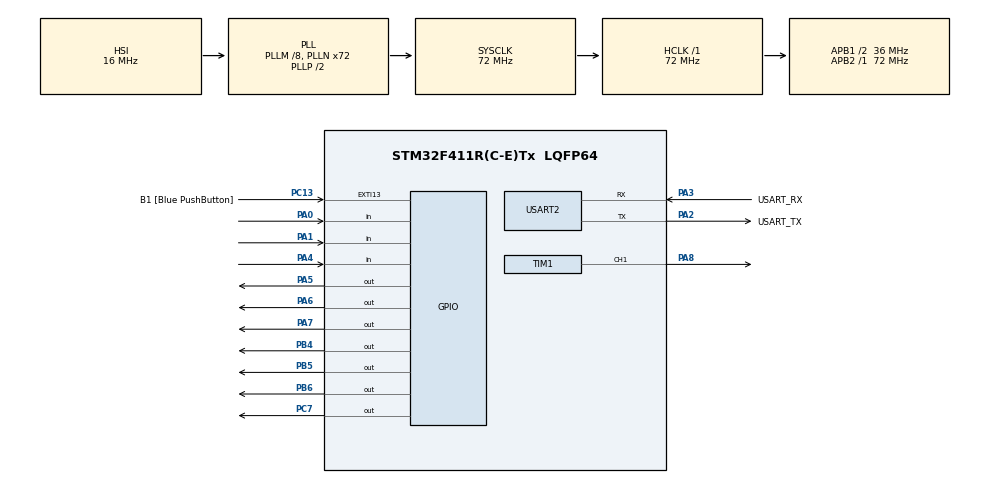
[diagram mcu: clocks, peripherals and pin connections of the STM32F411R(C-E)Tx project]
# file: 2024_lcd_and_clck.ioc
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Dma.Request0=TIM1_CH1
Dma.TIM1_CH1.0.Direction=DMA_PERIPH_TO_MEMORY
Dma.TIM1_CH1.0.FIFOMode=DMA_FIFOMODE_DISABLE
Dma.TIM1_CH1.0.Instance=DMA2_Stream1
Dma.TIM1_CH1.0.MemDataAlignment=DMA_MDATAALIGN_WORD
Dma.TIM1_CH1.0.MemInc=DMA_MINC_ENABLE
Dma.TIM1_CH1.0.Mode=DMA_NORMAL
Dma.TIM1_CH1.0.PeriphDataAlignment=DMA_PDATAALIGN_WORD
Dma.TIM1_CH1.0.PeriphInc=DMA_PINC_DISABLE
Dma.TIM1_CH1.0.Priority=DMA_PRIORITY_LOW
Mcu.Family=STM32F4
Mcu.Name=STM32F411R(C-E)Tx
Mcu.Package=LQFP64
NVIC.DMA2_Stream1_IRQn=true\:0\:0\:false\:false\:true\:false\:true\:true
NVIC.PriorityGroup=NVIC_PRIORITYGROUP_0
PA0-WKUP.Signal=GPIO_Input
PA1.Signal=GPIO_Input
PA13.GPIO_Label=TMS
PA13.Mode=Serial_Wire
PA13.Signal=SYS_JTMS-SWDIO
PA14.GPIO_Label=TCK
PA14.Mode=Serial_Wire
PA14.Signal=SYS_JTCK-SWCLK
PA2.GPIO_Label=USART_TX
PA2.Mode=Asynchronous
PA2.Signal=USART2_TX
PA3.GPIO_Label=USART_RX
PA3.Mode=Asynchronous
PA3.Signal=USART2_RX
PA4.Signal=GPIO_Input
PA5.Signal=GPIO_Output
PA6.Signal=GPIO_Output
PA7.Signal=GPIO_Output
PA8.Signal=S_TIM1_CH1
PB3.Signal=SYS_JTDO-SWO
PB4.Signal=GPIO_Output
PB5.Signal=GPIO_Output
PB6.Signal=GPIO_Output
PC13-ANTI_TAMP.GPIO_Label=B1 [Blue PushButton]
PC13-ANTI_TAMP.GPIO_ModeDefaultEXTI=GPIO_MODE_IT_FALLING
PC13-ANTI_TAMP.Signal=GPXTI13
PC14-OSC32_IN.Mode=LSE-External-Oscillator
PC14-OSC32_IN.Signal=RCC_OSC32_IN
PC15-OSC32_OUT.Mode=LSE-External-Oscillator
PC15-OSC32_OUT.Signal=RCC_OSC32_OUT
PC7.Signal=GPIO_Output
PH0\ -\ OSC_IN.Mode=HSE-External-Oscillator
PH0\ -\ OSC_IN.Signal=RCC_OSC_IN
PH1\ -\ OSC_OUT.Mode=HSE-External-Oscillator
PH1\ -\ OSC_OUT.Signal=RCC_OSC_OUT
ProjectManager.HeapSize=0x200
ProjectManager.StackSize=0x400
ProjectManager.TargetToolchain=STM32CubeIDE
RCC.48MHZClocksFreq_Value=36000000
RCC.AHBFreq_Value=72000000
RCC.APB1CLKDivider=RCC_HCLK_DIV2
RCC.APB1Freq_Value=36000000
RCC.APB1TimFreq_Value=72000000
RCC.APB2Freq_Value=72000000
RCC.APB2TimFreq_Value=72000000
RCC.CortexFreq_Value=72000000
RCC.FLatency-AdvancedSettings=FLASH_LATENCY_2
RCC.HCLKFreq_Value=72000000
RCC.HSE_VALUE=8000000
RCC.HSI_VALUE=16000000
RCC.PLLM=8
RCC.PLLN=72
RCC.SYSCLKFreq_VALUE=72000000
RCC.SYSCLKSource=RCC_SYSCLKSOURCE_PLLCLK
RCC.VCOOutputFreq_Value=144000000
SH.S_TIM1_CH1.0=TIM1_CH1,PWM Generation1 CH1
TIM1.AutoReloadPreload=TIM_AUTORELOAD_PRELOAD_ENABLE
TIM1.Channel-PWM\ Generation1\ CH1=TIM_CHANNEL_1
TIM1.Period=100
TIM1.Pulse-PWM\ Generation1\ CH1=25
USART2.VirtualMode=VM_ASYNC
VP_TIM1_VS_ClockSourceINT.Mode=Internal
board=NUCLEO-F411RE

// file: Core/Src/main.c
/* USER CODE BEGIN Header */
/**
 ******************************************************************************
 * @file           : main.c
 * @brief          : Main program body
 ******************************************************************************
 * @attention
 *
 * Copyright (c) 2024 STMicroelectronics.
 * All rights reserved.
 *
 * This software is licensed under terms that can be found in the LICENSE file
 * in the root directory of this software component.
 * If no LICENSE file comes with this software, it is provided AS-IS.
 *
 ******************************************************************************
 */
/* USER CODE END Header */
#include "main.h"

/* USER CODE BEGIN Includes */
#include "lcd.h"
/* USER CODE END Includes */

TIM_HandleTypeDef htim1;
DMA_HandleTypeDef hdma_tim1_ch1;

UART_HandleTypeDef huart2;

/* USER CODE BEGIN PV */
char buffer[40];
uint32_t time;
int waiting_time_for_push = 3000000, pa0Push, push_delay = 500, seconds;
int b, a, pwmPulse, light_sensor;
/* USER CODE END PV */

void SystemClock_Config(void);
static void MX_GPIO_Init(void);
static void MX_DMA_Init(void);
static void MX_USART2_UART_Init(void);
static void MX_TIM1_Init(void);

int main(void)
{

  /* MCU Configuration--------------------------------------------------------*/

  /* Reset of all peripherals, Initializes the Flash interface and the Systick. */
  HAL_Init();

  /* Configure the system clock */
  SystemClock_Config();

  /* Initialize all configured peripherals */
  MX_GPIO_Init();
  MX_DMA_Init();
  MX_USART2_UART_Init();
  MX_TIM1_Init();
  /* USER CODE BEGIN 2 */

  HAL_TIM_PWM_Start(&htim1, TIM_CHANNEL_1);

	Lcd_PortType ports[] = { GPIOC, GPIOB, GPIOA, GPIOA };
	// Lcd_PinType pins[] = {D4_Pin, D5_Pin, D6_Pin, D7_Pin};
	Lcd_PinType pins[] = {GPIO_PIN_7, GPIO_PIN_6, GPIO_PIN_7, GPIO_PIN_6};
	Lcd_HandleTypeDef lcd;
	// Lcd_create(ports, pins, RS_GPIO_Port, RS_Pin, EN_GPIO_Port, EN_Pin, LCD_4_BIT_MODE);
	lcd = Lcd_create(ports, pins, GPIOB, GPIO_PIN_5, GPIOB, GPIO_PIN_4, LCD_4_BIT_MODE);
	Lcd_cursor(&lcd, 0,1);
	Lcd_string(&lcd, "SECONDS OF START");
  /* USER CODE END 2 */

  /* Infinite loop */
	while (1)
	{

		__HAL_TIM_SET_COMPARE(&htim1, TIM_CHANNEL_1,pwmPulse);
		//------------------------

				time = HAL_GetTick();
				   Lcd_cursor(&lcd, 0,18);
				       Lcd_int(&lcd, time/1000);

				//"a" is main menu number
				if(a < 0){a = 0;}
				if(a > 5){a = 5;}
				sprintf(buffer, " Manual pwm  %d \r\n", b);
				HAL_UART_Transmit(&huart2, buffer, sizeof(buffer), HAL_MAX_DELAY);
				sprintf(buffer, "	Set number  %d \r\n",a);
				HAL_UART_Transmit(&huart2, buffer, sizeof(buffer), HAL_MAX_DELAY);

				if((b == 0))
				{pa0Push =0;
				pwmPulse = light_sensor;

				sprintf(buffer, "AUTO PWM  \r\n");
				HAL_UART_Transmit(&huart2, buffer, sizeof(buffer), HAL_MAX_DELAY);
				Lcd_cursor(&lcd, 1,1);
				Lcd_string(&lcd, "AUTO PWM                  ");

				while (HAL_GPIO_ReadPin (GPIOA, GPIO_PIN_4))
				{
					pa0Push++;

					if ( (pa0Push > waiting_time_for_push) )

					{	 b = 1;
					break;

					}
				}
				}

				if(b == 1)
				{
					pa0Push = 0;
					Lcd_cursor(&lcd, 1,1);
					Lcd_string(&lcd, "MANUAL PWM SET");

					if (HAL_GPIO_ReadPin (GPIOA, GPIO_PIN_0))
							{  a++;	//menu plus
							HAL_Delay (200);
							}

							if (HAL_GPIO_ReadPin (GPIOA, GPIO_PIN_1))
							{  a--;	//menu minus
							HAL_Delay (200);
							}

							if(a == 0)
																{
																	sprintf(buffer, "PWM OFF		\r\n");
																	HAL_UART_Transmit(&huart2, buffer, sizeof(buffer), HAL_MAX_DELAY);
																	Lcd_cursor(&lcd, 1,16);
																	Lcd_string(&lcd, "PWM OFF");
																	pwmPulse = 0;
																}

							if(a == 1)
											{
												sprintf(buffer, "PWM 20%%		\r\n");
												HAL_UART_Transmit(&huart2, buffer, sizeof(buffer), HAL_MAX_DELAY);
												Lcd_cursor(&lcd, 1,16);
												Lcd_string(&lcd, "PWM 20%            ");
												pwmPulse = 20;
											}
							if(a == 2)
																{
																	sprintf(buffer, "PWM 40%		\r\n");
																	HAL_UART_Transmit(&huart2, buffer, sizeof(buffer), HAL_MAX_DELAY);
																	Lcd_cursor(&lcd, 1,16);
																	Lcd_string(&lcd, "PWM 40%       ");
																	pwmPulse = 40;
																}
							if(a == 3)
																{
																	sprintf(buffer, "PWM 60% \r\n");
																	HAL_UART_Transmit(&huart2, buffer, sizeof(buffer), HAL_MAX_DELAY);
																	Lcd_cursor(&lcd, 1,16);
																	Lcd_string(&lcd, "PWM 60%  ");
																	pwmPulse =60;
																}
							if(a == 4)
																			{
																				sprintf(buffer, "PWM 80% \r\n");
																				HAL_UART_Transmit(&huart2, buffer, sizeof(buffer), HAL_MAX_DELAY);
																				Lcd_cursor(&lcd, 1,16);
																				Lcd_string(&lcd, "PWM 80%  ");
																				pwmPulse = 80;
																			}
							if(a == 5)
																			{
																				sprintf(buffer, "PWM 100% \r\n");
																				HAL_UART_Transmit(&huart2, buffer, sizeof(buffer), HAL_MAX_DELAY);
																				Lcd_cursor(&lcd, 1,16);
																				Lcd_string(&lcd, "PWM 100% ");
																				pwmPulse =100;
																			}

					while (HAL_GPIO_ReadPin (GPIOA, GPIO_PIN_4))
					{
						pa0Push++;

						if ( (pa0Push > waiting_time_for_push) )

						{	 b = 0;
						break;
						}
					}
				}

		//----------------
	}
}

void SystemClock_Config(void)
{
  RCC_OscInitTypeDef RCC_OscInitStruct = {0};
  RCC_ClkInitTypeDef RCC_ClkInitStruct = {0};

  /** Configure the main internal regulator output voltage
  */
  __HAL_RCC_PWR_CLK_ENABLE();
  __HAL_PWR_VOLTAGESCALING_CONFIG(PWR_REGULATOR_VOLTAGE_SCALE1);

  /** Initializes the RCC Oscillators according to the specified parameters
  * in the RCC_OscInitTypeDef structure.
  */
  RCC_OscInitStruct.OscillatorType = RCC_OSCILLATORTYPE_HSI;
  RCC_OscInitStruct.HSIState = RCC_HSI_ON;
  RCC_OscInitStruct.HSICalibrationValue = RCC_HSICALIBRATION_DEFAULT;
  RCC_OscInitStruct.PLL.PLLState = RCC_PLL_ON;
  RCC_OscInitStruct.PLL.PLLSource = RCC_PLLSOURCE_HSI;
  RCC_OscInitStruct.PLL.PLLM = 8;
  RCC_OscInitStruct.PLL.PLLN = 72;
  RCC_OscInitStruct.PLL.PLLP = RCC_PLLP_DIV2;
  RCC_OscInitStruct.PLL.PLLQ = 4;
  if (HAL_RCC_OscConfig(&RCC_OscInitStruct) != HAL_OK)
  {
    Error_Handler();
  }

  /** Initializes the CPU, AHB and APB buses clocks
  */
  RCC_ClkInitStruct.ClockType = RCC_CLOCKTYPE_HCLK|RCC_CLOCKTYPE_SYSCLK
                              |RCC_CLOCKTYPE_PCLK1|RCC_CLOCKTYPE_PCLK2;
  RCC_ClkInitStruct.SYSCLKSource = RCC_SYSCLKSOURCE_PLLCLK;
  RCC_ClkInitStruct.AHBCLKDivider = RCC_SYSCLK_DIV1;
  RCC_ClkInitStruct.APB1CLKDivider = RCC_HCLK_DIV2;
  RCC_ClkInitStruct.APB2CLKDivider = RCC_HCLK_DIV1;

  if (HAL_RCC_ClockConfig(&RCC_ClkInitStruct, FLASH_LATENCY_2) != HAL_OK)
  {
    Error_Handler();
  }
}

static void MX_TIM1_Init(void)
{

  TIM_ClockConfigTypeDef sClockSourceConfig = {0};
  TIM_MasterConfigTypeDef sMasterConfig = {0};
  TIM_OC_InitTypeDef sConfigOC = {0};
  TIM_BreakDeadTimeConfigTypeDef sBreakDeadTimeConfig = {0};

  htim1.Instance = TIM1;
  htim1.Init.Prescaler = 0;
  htim1.Init.CounterMode = TIM_COUNTERMODE_UP;
  htim1.Init.Period = 100;
  htim1.Init.ClockDivision = TIM_CLOCKDIVISION_DIV1;
  htim1.Init.RepetitionCounter = 0;
  htim1.Init.AutoReloadPreload = TIM_AUTORELOAD_PRELOAD_ENABLE;
  if (HAL_TIM_Base_Init(&htim1) != HAL_OK)
  {
    Error_Handler();
  }
  sClockSourceConfig.ClockSource = TIM_CLOCKSOURCE_INTERNAL;
  if (HAL_TIM_ConfigClockSource(&htim1, &sClockSourceConfig) != HAL_OK)
  {
    Error_Handler();
  }
  if (HAL_TIM_PWM_Init(&htim1) != HAL_OK)
  {
    Error_Handler();
  }
  sMasterConfig.MasterOutputTrigger = TIM_TRGO_RESET;
  sMasterConfig.MasterSlaveMode = TIM_MASTERSLAVEMODE_DISABLE;
  if (HAL_TIMEx_MasterConfigSynchronization(&htim1, &sMasterConfig) != HAL_OK)
  {
    Error_Handler();
  }
  sConfigOC.OCMode = TIM_OCMODE_PWM1;
  sConfigOC.Pulse = 25;
  sConfigOC.OCPolarity = TIM_OCPOLARITY_HIGH;
  sConfigOC.OCNPolarity = TIM_OCNPOLARITY_HIGH;
  sConfigOC.OCFastMode = TIM_OCFAST_DISABLE;
  sConfigOC.OCIdleState = TIM_OCIDLESTATE_RESET;
  sConfigOC.OCNIdleState = TIM_OCNIDLESTATE_RESET;
  if (HAL_TIM_PWM_ConfigChannel(&htim1, &sConfigOC, TIM_CHANNEL_1) != HAL_OK)
  {
    Error_Handler();
  }
  sBreakDeadTimeConfig.OffStateRunMode = TIM_OSSR_DISABLE;
  sBreakDeadTimeConfig.OffStateIDLEMode = TIM_OSSI_DISABLE;
  sBreakDeadTimeConfig.LockLevel = TIM_LOCKLEVEL_OFF;
  sBreakDeadTimeConfig.DeadTime = 0;
  sBreakDeadTimeConfig.BreakState = TIM_BREAK_DISABLE;
  sBreakDeadTimeConfig.BreakPolarity = TIM_BREAKPOLARITY_HIGH;
  sBreakDeadTimeConfig.AutomaticOutput = TIM_AUTOMATICOUTPUT_DISABLE;
  if (HAL_TIMEx_ConfigBreakDeadTime(&htim1, &sBreakDeadTimeConfig) != HAL_OK)
  {
    Error_Handler();
  }
  HAL_TIM_MspPostInit(&htim1);

}

static void MX_USART2_UART_Init(void)
{

  huart2.Instance = USART2;
  huart2.Init.BaudRate = 115200;
  huart2.Init.WordLength = UART_WORDLENGTH_8B;
  huart2.Init.StopBits = UART_STOPBITS_1;
  huart2.Init.Parity = UART_PARITY_NONE;
  huart2.Init.Mode = UART_MODE_TX_RX;
  huart2.Init.HwFlowCtl = UART_HWCONTROL_NONE;
  huart2.Init.OverSampling = UART_OVERSAMPLING_16;
  if (HAL_UART_Init(&huart2) != HAL_OK)
  {
    Error_Handler();
  }

}

static void MX_DMA_Init(void)
{

  /* DMA controller clock enable */
  __HAL_RCC_DMA2_CLK_ENABLE();

  /* DMA interrupt init */
  /* DMA2_Stream1_IRQn interrupt configuration */
  HAL_NVIC_SetPriority(DMA2_Stream1_IRQn, 0, 0);
  HAL_NVIC_EnableIRQ(DMA2_Stream1_IRQn);

}

static void MX_GPIO_Init(void)
{
  GPIO_InitTypeDef GPIO_InitStruct = {0};

  /* GPIO Ports Clock Enable */
  __HAL_RCC_GPIOC_CLK_ENABLE();
  __HAL_RCC_GPIOH_CLK_ENABLE();
  __HAL_RCC_GPIOA_CLK_ENABLE();
  __HAL_RCC_GPIOB_CLK_ENABLE();

  /*Configure GPIO pin Output Level */
  HAL_GPIO_WritePin(GPIOA, GPIO_PIN_5|GPIO_PIN_6|GPIO_PIN_7, GPIO_PIN_RESET);

  /*Configure GPIO pin Output Level */
  HAL_GPIO_WritePin(GPIOC, GPIO_PIN_7, GPIO_PIN_RESET);

  /*Configure GPIO pin Output Level */
  HAL_GPIO_WritePin(GPIOB, GPIO_PIN_4|GPIO_PIN_5|GPIO_PIN_6, GPIO_PIN_RESET);

  /*Configure GPIO pin : B1_Pin */
  GPIO_InitStruct.Pin = B1_Pin;
  GPIO_InitStruct.Mode = GPIO_MODE_IT_FALLING;
  GPIO_InitStruct.Pull = GPIO_NOPULL;
  HAL_GPIO_Init(B1_GPIO_Port, &GPIO_InitStruct);

  /*Configure GPIO pins : PA0 PA1 PA4 */
  GPIO_InitStruct.Pin = GPIO_PIN_0|GPIO_PIN_1|GPIO_PIN_4;
  GPIO_InitStruct.Mode = GPIO_MODE_INPUT;
  GPIO_InitStruct.Pull = GPIO_NOPULL;
  HAL_GPIO_Init(GPIOA, &GPIO_InitStruct);

  /*Configure GPIO pins : PA5 PA6 PA7 */
  GPIO_InitStruct.Pin = GPIO_PIN_5|GPIO_PIN_6|GPIO_PIN_7;
  GPIO_InitStruct.Mode = GPIO_MODE_OUTPUT_PP;
  GPIO_InitStruct.Pull = GPIO_NOPULL;
  GPIO_InitStruct.Speed = GPIO_SPEED_FREQ_LOW;
  HAL_GPIO_Init(GPIOA, &GPIO_InitStruct);

  /*Configure GPIO pin : PC7 */
  GPIO_InitStruct.Pin = GPIO_PIN_7;
  GPIO_InitStruct.Mode = GPIO_MODE_OUTPUT_PP;
  GPIO_InitStruct.Pull = GPIO_NOPULL;
  GPIO_InitStruct.Speed = GPIO_SPEED_FREQ_LOW;
  HAL_GPIO_Init(GPIOC, &GPIO_InitStruct);

  /*Configure GPIO pins : PB4 PB5 PB6 */
  GPIO_InitStruct.Pin = GPIO_PIN_4|GPIO_PIN_5|GPIO_PIN_6;
  GPIO_InitStruct.Mode = GPIO_MODE_OUTPUT_PP;
  GPIO_InitStruct.Pull = GPIO_NOPULL;
  GPIO_InitStruct.Speed = GPIO_SPEED_FREQ_LOW;
  HAL_GPIO_Init(GPIOB, &GPIO_InitStruct);

}

void Error_Handler(void)
{
	__disable_irq();
	while (1)
	{
	}
}
